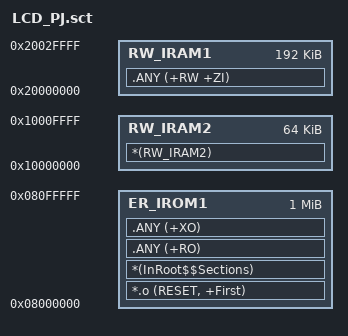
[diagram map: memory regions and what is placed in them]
; *************************************************************
; *** Scatter-Loading Description File generated by uVision ***
; *************************************************************

LR_IROM1 0x08000000 0x00100000  {

  ER_IROM1 0x08000000 0x00100000  {
    *.o (RESET, +First)
    *(InRoot$$Sections)
    .ANY (+RO)
    .ANY (+XO)
  }

  ; ------------------------------
  ; 普通 SRAM（主RAM）
  ; ------------------------------
  RW_IRAM1 0x20000000 0x00030000  {
    .ANY (+RW +ZI)        ; 默认变量全部进这里
  }

  ; ------------------------------
  ; CCM RAM（手动放）
  ; ------------------------------
  RW_IRAM2 0x10000000 0x00010000  {
    *(RW_IRAM2)           ; 只放指定 section
  }
}

